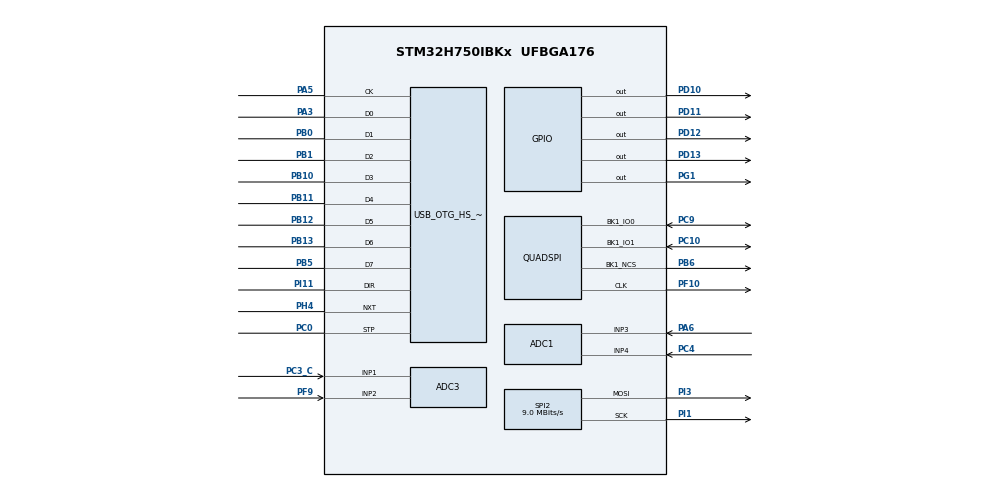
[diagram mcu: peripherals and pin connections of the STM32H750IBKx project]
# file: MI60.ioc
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ADC1.Channel-0\#ChannelRegularConversion=ADC_CHANNEL_3
ADC1.Channel-1\#ChannelRegularConversion=ADC_CHANNEL_4
ADC1.ContinuousConvMode=ENABLE
ADC1.ConversionDataManagement=ADC_CONVERSIONDATA_DMA_CIRCULAR
ADC1.NbrOfConversion=2
ADC1.NbrOfConversionFlag=1
ADC1.OffsetNumber-0\#ChannelRegularConversion=ADC_OFFSET_NONE
ADC1.OffsetNumber-1\#ChannelRegularConversion=ADC_OFFSET_NONE
ADC1.OffsetSignedSaturation-0\#ChannelRegularConversion=DISABLE
ADC1.OffsetSignedSaturation-1\#ChannelRegularConversion=DISABLE
ADC1.Overrun=ADC_OVR_DATA_OVERWRITTEN
ADC1.OversamplingMode=ENABLE
ADC1.Rank-0\#ChannelRegularConversion=1
ADC1.Rank-1\#ChannelRegularConversion=2
ADC1.Ratio=16
ADC1.RightBitShift=ADC_RIGHTBITSHIFT_2
ADC1.SamplingTime-0\#ChannelRegularConversion=ADC_SAMPLETIME_1CYCLE_5
ADC1.SamplingTime-1\#ChannelRegularConversion=ADC_SAMPLETIME_1CYCLE_5
ADC1.master=1
ADC3.Channel-2\#ChannelRegularConversion=ADC_CHANNEL_1
ADC3.Channel-3\#ChannelRegularConversion=ADC_CHANNEL_2
ADC3.ClockPrescalerADC3=ADC_CLOCK_ASYNC_DIV8
ADC3.ContinuousConvMode=ENABLE
ADC3.ConversionDataManagement=ADC_CONVERSIONDATA_DMA_CIRCULAR
ADC3.DiscontinuousConvMode=DISABLE
ADC3.NbrOfConversion=2
ADC3.NbrOfConversionFlag=1
ADC3.OffsetNumber-2\#ChannelRegularConversion=ADC_OFFSET_NONE
ADC3.OffsetNumber-3\#ChannelRegularConversion=ADC_OFFSET_NONE
ADC3.OffsetSignedSaturation-2\#ChannelRegularConversion=DISABLE
ADC3.OffsetSignedSaturation-3\#ChannelRegularConversion=DISABLE
ADC3.Overrun=ADC_OVR_DATA_OVERWRITTEN
ADC3.OversamplingMode=ENABLE
ADC3.Rank-2\#ChannelRegularConversion=1
ADC3.Rank-3\#ChannelRegularConversion=2
ADC3.Ratio=16
ADC3.RightBitShift=ADC_RIGHTBITSHIFT_2
ADC3.SamplingTime-2\#ChannelRegularConversion=ADC_SAMPLETIME_1CYCLE_5
ADC3.SamplingTime-3\#ChannelRegularConversion=ADC_SAMPLETIME_1CYCLE_5
Bdma.ADC3.0.Direction=DMA_PERIPH_TO_MEMORY
Bdma.ADC3.0.EventEnable=DISABLE
Bdma.ADC3.0.Instance=BDMA_Channel0
Bdma.ADC3.0.MemDataAlignment=DMA_MDATAALIGN_HALFWORD
Bdma.ADC3.0.MemInc=DMA_MINC_ENABLE
Bdma.ADC3.0.Mode=DMA_CIRCULAR
Bdma.ADC3.0.PeriphDataAlignment=DMA_PDATAALIGN_HALFWORD
Bdma.ADC3.0.PeriphInc=DMA_PINC_DISABLE
Bdma.ADC3.0.Polarity=HAL_DMAMUX_REQ_GEN_RISING
Bdma.ADC3.0.Priority=DMA_PRIORITY_VERY_HIGH
Bdma.ADC3.0.RequestNumber=1
Bdma.ADC3.0.SignalID=NONE
Bdma.ADC3.0.SyncEnable=DISABLE
Bdma.ADC3.0.SyncPolarity=HAL_DMAMUX_SYNC_NO_EVENT
Bdma.ADC3.0.SyncRequestNumber=1
Bdma.ADC3.0.SyncSignalID=NONE
Bdma.Request0=ADC3
Bdma.RequestsNb=1
CORTEX_M7.AccessPermission_S-Cortex_Memory_Protection_Unit_Region1_Settings_S=MPU_REGION_FULL_ACCESS
CORTEX_M7.AccessPermission_S-Cortex_Memory_Protection_Unit_Region2_Settings_S=MPU_REGION_FULL_ACCESS
CORTEX_M7.AccessPermission_S-Cortex_Memory_Protection_Unit_Region3_Settings_S=MPU_REGION_FULL_ACCESS
CORTEX_M7.AccessPermission_S-Cortex_Memory_Protection_Unit_Region4_Settings_S=MPU_REGION_FULL_ACCESS
CORTEX_M7.AccessPermission_S-Cortex_Memory_Protection_Unit_Region5_Settings_S=MPU_REGION_FULL_ACCESS
CORTEX_M7.AccessPermission_Spec=MPU_REGION_FULL_ACCESS
CORTEX_M7.BaseAddress_S-Cortex_Memory_Protection_Unit_Region1_Settings_S=0x60000000
CORTEX_M7.BaseAddress_S-Cortex_Memory_Protection_Unit_Region2_Settings_S=0x30000000
CORTEX_M7.BaseAddress_S-Cortex_Memory_Protection_Unit_Region3_Settings_S=0x30020000
CORTEX_M7.BaseAddress_S-Cortex_Memory_Protection_Unit_Region4_Settings_S=0x30040000
CORTEX_M7.BaseAddress_S-Cortex_Memory_Protection_Unit_Region5_Settings_S=0x38000000
CORTEX_M7.BaseAddress_Spec=0x24000000
CORTEX_M7.CPU_DCache=Enabled
CORTEX_M7.CPU_ICache=Enabled
CORTEX_M7.DisableExec_Spec=MPU_INSTRUCTION_ACCESS_ENABLE
CORTEX_M7.Enable_S-Cortex_Memory_Protection_Unit_Region1_Settings_S=MPU_REGION_ENABLE
CORTEX_M7.Enable_S-Cortex_Memory_Protection_Unit_Region2_Settings_S=MPU_REGION_ENABLE
CORTEX_M7.Enable_S-Cortex_Memory_Protection_Unit_Region3_Settings_S=MPU_REGION_ENABLE
CORTEX_M7.Enable_S-Cortex_Memory_Protection_Unit_Region4_Settings_S=MPU_REGION_ENABLE
CORTEX_M7.Enable_S-Cortex_Memory_Protection_Unit_Region5_Settings_S=MPU_REGION_ENABLE
CORTEX_M7.IsBufferable_S-Cortex_Memory_Protection_Unit_Region1_Settings_S=MPU_ACCESS_BUFFERABLE
CORTEX_M7.IsBufferable_Spec=MPU_ACCESS_BUFFERABLE
CORTEX_M7.IsCacheable_S-Cortex_Memory_Protection_Unit_Region2_Settings_S=MPU_ACCESS_CACHEABLE
CORTEX_M7.IsCacheable_S-Cortex_Memory_Protection_Unit_Region3_Settings_S=MPU_ACCESS_CACHEABLE
CORTEX_M7.IsCacheable_S-Cortex_Memory_Protection_Unit_Region4_Settings_S=MPU_ACCESS_CACHEABLE
CORTEX_M7.IsCacheable_S-Cortex_Memory_Protection_Unit_Region5_Settings_S=MPU_ACCESS_CACHEABLE
CORTEX_M7.IsCacheable_Spec=MPU_ACCESS_CACHEABLE
CORTEX_M7.IsShareable_Spec=MPU_ACCESS_NOT_SHAREABLE
CORTEX_M7.MPU_Control=MPU_HFNMI_PRIVDEF
CORTEX_M7.Size_S-Cortex_Memory_Protection_Unit_Region1_Settings_S=MPU_REGION_SIZE_64KB
CORTEX_M7.Size_S-Cortex_Memory_Protection_Unit_Region2_Settings_S=MPU_REGION_SIZE_128KB
CORTEX_M7.Size_S-Cortex_Memory_Protection_Unit_Region3_Settings_S=MPU_REGION_SIZE_128KB
CORTEX_M7.Size_S-Cortex_Memory_Protection_Unit_Region4_Settings_S=MPU_REGION_SIZE_32KB
CORTEX_M7.Size_S-Cortex_Memory_Protection_Unit_Region5_Settings_S=MPU_REGION_SIZE_64KB
CORTEX_M7.Size_Spec=MPU_REGION_SIZE_512KB
CORTEX_M7.SubRegionDisable_Spec=0x0
CORTEX_M7.TypeExtField_Spec=MPU_TEX_LEVEL1
CORTEX_M7.default_mode_Activation=1
Dma.ADC1.1.Direction=DMA_PERIPH_TO_MEMORY
Dma.ADC1.1.EventEnable=DISABLE
Dma.ADC1.1.FIFOMode=DMA_FIFOMODE_DISABLE
Dma.ADC1.1.Instance=DMA1_Stream5
Dma.ADC1.1.MemDataAlignment=DMA_MDATAALIGN_HALFWORD
Dma.ADC1.1.MemInc=DMA_MINC_ENABLE
Dma.ADC1.1.Mode=DMA_CIRCULAR
Dma.ADC1.1.PeriphDataAlignment=DMA_PDATAALIGN_HALFWORD
Dma.ADC1.1.PeriphInc=DMA_PINC_DISABLE
Dma.ADC1.1.Polarity=HAL_DMAMUX_REQ_GEN_RISING
Dma.ADC1.1.Priority=DMA_PRIORITY_VERY_HIGH
Dma.ADC1.1.RequestNumber=1
Dma.ADC1.1.SignalID=NONE
Dma.ADC1.1.SyncEnable=DISABLE
Dma.ADC1.1.SyncPolarity=HAL_DMAMUX_SYNC_NO_EVENT
Dma.ADC1.1.SyncRequestNumber=1
Dma.ADC1.1.SyncSignalID=NONE
Dma.Request0=SPI2_TX
Dma.Request1=ADC1
Dma.SPI2_TX.0.Direction=DMA_MEMORY_TO_PERIPH
Dma.SPI2_TX.0.EventEnable=DISABLE
Dma.SPI2_TX.0.FIFOMode=DMA_FIFOMODE_DISABLE
Dma.SPI2_TX.0.Instance=DMA1_Stream0
Dma.SPI2_TX.0.MemDataAlignment=DMA_MDATAALIGN_BYTE
Dma.SPI2_TX.0.MemInc=DMA_MINC_ENABLE
Dma.SPI2_TX.0.Mode=DMA_NORMAL
Dma.SPI2_TX.0.PeriphDataAlignment=DMA_PDATAALIGN_BYTE
Dma.SPI2_TX.0.PeriphInc=DMA_PINC_DISABLE
Dma.SPI2_TX.0.Polarity=HAL_DMAMUX_REQ_GEN_RISING
Dma.SPI2_TX.0.Priority=DMA_PRIORITY_LOW
Dma.SPI2_TX.0.RequestNumber=1
Dma.SPI2_TX.0.SignalID=NONE
Dma.SPI2_TX.0.SyncEnable=DISABLE
Dma.SPI2_TX.0.SyncPolarity=HAL_DMAMUX_SYNC_NO_EVENT
Dma.SPI2_TX.0.SyncRequestNumber=1
Dma.SPI2_TX.0.SyncSignalID=NONE
Mcu.Family=STM32H7
Mcu.Name=STM32H750IBKx
Mcu.Package=UFBGA176
NVIC.ADC3_IRQn=true\:0\:0\:false\:false\:true\:true\:true\:true
NVIC.ADC_IRQn=true\:0\:0\:false\:false\:true\:true\:true\:true
NVIC.BDMA_Channel0_IRQn=true\:0\:0\:false\:false\:true\:false\:true\:true
NVIC.DMA1_Stream0_IRQn=true\:2\:0\:true\:false\:true\:false\:true\:true
NVIC.DMA1_Stream5_IRQn=true\:0\:0\:true\:false\:true\:false\:true\:true
NVIC.OTG_HS_IRQn=true\:0\:0\:false\:false\:true\:true\:true\:true
NVIC.PriorityGroup=NVIC_PRIORITYGROUP_4
NVIC.SPI2_IRQn=true\:2\:0\:true\:false\:true\:false\:true\:true
NVIC.TIM5_IRQn=true\:0\:0\:false\:false\:true\:true\:true\:true
PA13\ (JTMS/SWDIO).Mode=Serial_Wire
PA13\ (JTMS/SWDIO).Signal=DEBUG_JTMS-SWDIO
PA14\ (JTCK/SWCLK).Mode=Serial_Wire
PA14\ (JTCK/SWCLK).Signal=DEBUG_JTCK-SWCLK
PA3.Mode=Device_HS
PA3.Signal=USB_OTG_HS_ULPI_D0
PA5.Mode=Device_HS
PA5.Signal=USB_OTG_HS_ULPI_CK
PA6.Signal=ADCx_INP3
PB0.Mode=Device_HS
PB0.Signal=USB_OTG_HS_ULPI_D1
PB1.Mode=Device_HS
PB1.Signal=USB_OTG_HS_ULPI_D2
PB10.Mode=Device_HS
PB10.Signal=USB_OTG_HS_ULPI_D3
PB11.Mode=Device_HS
PB11.Signal=USB_OTG_HS_ULPI_D4
PB12.Mode=Device_HS
PB12.Signal=USB_OTG_HS_ULPI_D5
PB13.Mode=Device_HS
PB13.Signal=USB_OTG_HS_ULPI_D6
PB5.Mode=Device_HS
PB5.Signal=USB_OTG_HS_ULPI_D7
PB6.Mode=Single Bank 1 2IOs
PB6.Signal=QUADSPI_BK1_NCS
PC0.Mode=Device_HS
PC0.Signal=USB_OTG_HS_ULPI_STP
PC10.Mode=Single Bank 1 2IOs
PC10.Signal=QUADSPI_BK1_IO1
PC3_C.Mode=IN1-Single-Ended
PC3_C.Signal=ADC3_INP1
PC4.Signal=ADCx_INP4
PC9.Mode=Single Bank 1 2IOs
PC9.Signal=QUADSPI_BK1_IO0
PD10.GPIO_ModeDefaultOutputPP=GPIO_MODE_OUTPUT_OD
PD10.GPIO_PuPd=GPIO_PULLUP
PD10.GPIO_Speed=GPIO_SPEED_FREQ_VERY_HIGH
PD10.Signal=GPIO_Output
PD11.GPIO_ModeDefaultOutputPP=GPIO_MODE_OUTPUT_OD
PD11.GPIO_PuPd=GPIO_PULLUP
PD11.GPIO_Speed=GPIO_SPEED_FREQ_VERY_HIGH
PD11.Signal=GPIO_Output
PD12.GPIO_ModeDefaultOutputPP=GPIO_MODE_OUTPUT_OD
PD12.GPIO_PuPd=GPIO_PULLUP
PD12.GPIO_Speed=GPIO_SPEED_FREQ_VERY_HIGH
PD12.Signal=GPIO_Output
PD13.GPIO_ModeDefaultOutputPP=GPIO_MODE_OUTPUT_OD
PD13.GPIO_PuPd=GPIO_PULLUP
PD13.GPIO_Speed=GPIO_SPEED_FREQ_VERY_HIGH
PD13.Signal=GPIO_Output
PF10.Mode=Single Bank 1 2IOs
PF10.Signal=QUADSPI_CLK
PF9.Mode=IN2-Single-Ended
PF9.Signal=ADC3_INP2
PG1.Signal=GPIO_Output
PH0-OSC_IN\ (PH0).Mode=HSE-External-Oscillator
PH0-OSC_IN\ (PH0).Signal=RCC_OSC_IN
PH1-OSC_OUT\ (PH1).Mode=HSE-External-Oscillator
PH1-OSC_OUT\ (PH1).Signal=RCC_OSC_OUT
PH4.Mode=Device_HS
PH4.Signal=USB_OTG_HS_ULPI_NXT
PI1.Mode=TX_Only_Simplex_Unidirect_Master
PI1.Signal=SPI2_SCK
PI11.Mode=Device_HS
PI11.Signal=USB_OTG_HS_ULPI_DIR
PI3.Mode=TX_Only_Simplex_Unidirect_Master
PI3.Signal=SPI2_MOSI
ProjectManager.HeapSize=0x800
ProjectManager.StackSize=0x1000
ProjectManager.TargetToolchain=STM32CubeIDE
RCC.ADCFreq_Value=72000000
RCC.APB1Freq_Value=120000000
RCC.APB2Freq_Value=120000000
RCC.APB3Freq_Value=120000000
RCC.APB4Freq_Value=120000000
RCC.CortexFreq_Value=480000000
RCC.D1PPRE=RCC_APB3_DIV2
RCC.D2PPRE1=RCC_APB1_DIV2
RCC.D2PPRE2=RCC_APB2_DIV2
RCC.D3PPRE=RCC_APB4_DIV2
RCC.DIVM1=4
RCC.DIVM2=4
RCC.DIVM3=12
RCC.DIVN1=80
RCC.DIVN2=18
RCC.DIVN3=80
RCC.DIVP2=3
RCC.DIVP3=4
RCC.DIVR3=20
RCC.HCLKFreq_Value=240000000
RCC.HPRE=RCC_HCLK_DIV2
RCC.HSE_VALUE=48000000
RCC.PLL2FRACN=0
RCC.PLL3FRACN=0
RCC.PLLFRACN=0
RCC.PLLSourceVirtual=RCC_PLLSOURCE_HSE
RCC.ProductRev=revV
RCC.SPI123CLockSelection=RCC_SPI123CLKSOURCE_PLL2
RCC.SYSCLKFreq_VALUE=480000000
RCC.SYSCLKSource=RCC_SYSCLKSOURCE_PLLCLK
RCC.USBCLockSelection=RCC_USBCLKSOURCE_HSI48
RCC.USBFreq_Value=48000000
SH.ADCx_INP3.0=ADC1_INP3,IN3-Single-Ended
SH.ADCx_INP4.0=ADC1_INP4,IN4-Single-Ended
SPI2.BaudRatePrescaler=SPI_BAUDRATEPRESCALER_8
SPI2.CLKPhase=SPI_PHASE_1EDGE
SPI2.CalculateBaudRate=9.0 MBits/s
SPI2.DataSize=SPI_DATASIZE_8BIT
SPI2.Direction=SPI_DIRECTION_2LINES_TXONLY
SPI2.Mode=SPI_MODE_MASTER
SPI2.VirtualType=VM_MASTER
TIM5.Period=124
TIM5.Prescaler=479
USB_DEVICE.CLASS_NAME_HS=CUSTOM_HID
USB_DEVICE.CUSTOM_HID_HS_BINTERVAL=0x1
USB_DEVICE.USBD_CUSTOMHID_OUTREPORT_BUF_SIZE-CUSTOM_HID_HS=64
USB_DEVICE.USBD_CUSTOM_HID_REPORT_DESC_SIZE-CUSTOM_HID_HS=89
USB_DEVICE.VirtualMode-CUSTOM_HID_HS=CustomHid
USB_DEVICE.VirtualModeHS=Custom_Hid_HS
USB_OTG_HS.VirtualMode-Device_HS=Device_HS
USB_OTG_HS.dma_enable-Device_HS=ENABLE
VP_RNG_VS_RNG.Mode=RNG_Activate
VP_TIM5_VS_ClockSourceINT.Mode=Internal
VP_USB_DEVICE_VS_USB_DEVICE_CUSTOM_HID_HS.Mode=CUSTOM_HID_HS
board=custom

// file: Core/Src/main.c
/* USER CODE BEGIN Header */
/**
  ******************************************************************************
  * @file           : main.c
  * @brief          : Main program body
  ******************************************************************************
  * @attention
  *
  * Copyright (c) 2023 STMicroelectronics.
  * All rights reserved.
  *
  * This software is licensed under terms that can be found in the LICENSE file
  * in the root directory of this software component.
  * If no LICENSE file comes with this software, it is provided AS-IS.
  *
  ******************************************************************************
  */
/* USER CODE END Header */
#include "main.h"
#include "usb_device.h"

/* USER CODE BEGIN Includes */
#include "common_inc.h"
/* USER CODE END Includes */

ADC_HandleTypeDef hadc1;
ADC_HandleTypeDef hadc3;
DMA_HandleTypeDef hdma_adc1;
DMA_HandleTypeDef hdma_adc3;

QSPI_HandleTypeDef hqspi;

RNG_HandleTypeDef hrng;

SPI_HandleTypeDef hspi2;
DMA_HandleTypeDef hdma_spi2_tx;

TIM_HandleTypeDef htim5;

/* USER CODE BEGIN PV */
ALIGN_32BYTES(__attribute__((section(".RAM_D3"))) uint16_t ADC_BUF[4]);    //tip
__attribute__((section(".RAM_D1"))) uint8_t sfBuffer[4096];  //SPI flash buffer
__attribute__((section(".RAM_D1"))) uint8_t txBuffer[4096];  //todo
/* USER CODE END PV */

void SystemClock_Config(void);
void PeriphCommonClock_Config(void);
static void MPU_Config(void);
static void MX_GPIO_Init(void);
static void MX_BDMA_Init(void);
static void MX_DMA_Init(void);
static void MX_ADC3_Init(void);
static void MX_SPI2_Init(void);
static void MX_TIM5_Init(void);
static void MX_ADC1_Init(void);
static void MX_RNG_Init(void);
static void MX_QUADSPI_Init(void);

int main(void)
{

  /* MPU Configuration--------------------------------------------------------*/
  MPU_Config();

  /* Enable I-Cache---------------------------------------------------------*/
  SCB_EnableICache();

  /* Enable D-Cache---------------------------------------------------------*/
  SCB_EnableDCache();

  /* MCU Configuration--------------------------------------------------------*/

  /* Reset of all peripherals, Initializes the Flash interface and the Systick. */
  HAL_Init();

  /* Configure the system clock */
  SystemClock_Config();

/* Configure the peripherals common clocks */
  PeriphCommonClock_Config();

  /* Initialize all configured peripherals */
  MX_GPIO_Init();
  MX_BDMA_Init();
  MX_DMA_Init();
  MX_USB_DEVICE_Init();
  MX_ADC3_Init();
  MX_SPI2_Init();
  MX_TIM5_Init();
  MX_ADC1_Init();
  MX_RNG_Init();
  MX_QUADSPI_Init();
  /* USER CODE BEGIN 2 */
  //ADC self calibration
    HAL_ADCEx_Calibration_Start(&hadc3, ADC_CALIB_OFFSET_LINEARITY, ADC_SINGLE_ENDED);
    HAL_ADCEx_Calibration_Start(&hadc1, ADC_CALIB_OFFSET_LINEARITY, ADC_SINGLE_ENDED);
    //main function
    KeyboardMain();
  /* USER CODE END 2 */

  /* Infinite loop */
  while (1)
  {

  }
}

void SystemClock_Config(void)
{
  RCC_OscInitTypeDef RCC_OscInitStruct = {0};
  RCC_ClkInitTypeDef RCC_ClkInitStruct = {0};

  /** Supply configuration update enable
  */
  HAL_PWREx_ConfigSupply(PWR_LDO_SUPPLY);

  /** Configure the main internal regulator output voltage
  */
  __HAL_PWR_VOLTAGESCALING_CONFIG(PWR_REGULATOR_VOLTAGE_SCALE1);

  while(!__HAL_PWR_GET_FLAG(PWR_FLAG_VOSRDY)) {}

  __HAL_RCC_SYSCFG_CLK_ENABLE();
  __HAL_PWR_VOLTAGESCALING_CONFIG(PWR_REGULATOR_VOLTAGE_SCALE0);

  while(!__HAL_PWR_GET_FLAG(PWR_FLAG_VOSRDY)) {}

  /** Initializes the RCC Oscillators according to the specified parameters
  * in the RCC_OscInitTypeDef structure.
  */
  RCC_OscInitStruct.OscillatorType = RCC_OSCILLATORTYPE_HSI48|RCC_OSCILLATORTYPE_HSE;
  RCC_OscInitStruct.HSEState = RCC_HSE_ON;
  RCC_OscInitStruct.HSI48State = RCC_HSI48_ON;
  RCC_OscInitStruct.PLL.PLLState = RCC_PLL_ON;
  RCC_OscInitStruct.PLL.PLLSource = RCC_PLLSOURCE_HSE;
  RCC_OscInitStruct.PLL.PLLM = 4;
  RCC_OscInitStruct.PLL.PLLN = 80;
  RCC_OscInitStruct.PLL.PLLP = 2;
  RCC_OscInitStruct.PLL.PLLQ = 2;
  RCC_OscInitStruct.PLL.PLLR = 2;
  RCC_OscInitStruct.PLL.PLLRGE = RCC_PLL1VCIRANGE_3;
  RCC_OscInitStruct.PLL.PLLVCOSEL = RCC_PLL1VCOWIDE;
  RCC_OscInitStruct.PLL.PLLFRACN = 0;
  if (HAL_RCC_OscConfig(&RCC_OscInitStruct) != HAL_OK)
  {
    Error_Handler();
  }

  /** Initializes the CPU, AHB and APB buses clocks
  */
  RCC_ClkInitStruct.ClockType = RCC_CLOCKTYPE_HCLK|RCC_CLOCKTYPE_SYSCLK
                              |RCC_CLOCKTYPE_PCLK1|RCC_CLOCKTYPE_PCLK2
                              |RCC_CLOCKTYPE_D3PCLK1|RCC_CLOCKTYPE_D1PCLK1;
  RCC_ClkInitStruct.SYSCLKSource = RCC_SYSCLKSOURCE_PLLCLK;
  RCC_ClkInitStruct.SYSCLKDivider = RCC_SYSCLK_DIV1;
  RCC_ClkInitStruct.AHBCLKDivider = RCC_HCLK_DIV2;
  RCC_ClkInitStruct.APB3CLKDivider = RCC_APB3_DIV2;
  RCC_ClkInitStruct.APB1CLKDivider = RCC_APB1_DIV2;
  RCC_ClkInitStruct.APB2CLKDivider = RCC_APB2_DIV2;
  RCC_ClkInitStruct.APB4CLKDivider = RCC_APB4_DIV2;

  if (HAL_RCC_ClockConfig(&RCC_ClkInitStruct, FLASH_LATENCY_4) != HAL_OK)
  {
    Error_Handler();
  }
}

void PeriphCommonClock_Config(void)
{
  RCC_PeriphCLKInitTypeDef PeriphClkInitStruct = {0};

  /** Initializes the peripherals clock
  */
  PeriphClkInitStruct.PeriphClockSelection = RCC_PERIPHCLK_ADC|RCC_PERIPHCLK_SPI2;
  PeriphClkInitStruct.PLL2.PLL2M = 4;
  PeriphClkInitStruct.PLL2.PLL2N = 18;
  PeriphClkInitStruct.PLL2.PLL2P = 3;
  PeriphClkInitStruct.PLL2.PLL2Q = 2;
  PeriphClkInitStruct.PLL2.PLL2R = 2;
  PeriphClkInitStruct.PLL2.PLL2RGE = RCC_PLL2VCIRANGE_3;
  PeriphClkInitStruct.PLL2.PLL2VCOSEL = RCC_PLL2VCOWIDE;
  PeriphClkInitStruct.PLL2.PLL2FRACN = 0;
  PeriphClkInitStruct.Spi123ClockSelection = RCC_SPI123CLKSOURCE_PLL2;
  PeriphClkInitStruct.AdcClockSelection = RCC_ADCCLKSOURCE_PLL2;
  if (HAL_RCCEx_PeriphCLKConfig(&PeriphClkInitStruct) != HAL_OK)
  {
    Error_Handler();
  }
}

static void MX_ADC1_Init(void)
{

  ADC_MultiModeTypeDef multimode = {0};
  ADC_ChannelConfTypeDef sConfig = {0};

  /** Common config
  */
  hadc1.Instance = ADC1;
  hadc1.Init.ClockPrescaler = ADC_CLOCK_ASYNC_DIV1;
  hadc1.Init.Resolution = ADC_RESOLUTION_16B;
  hadc1.Init.ScanConvMode = ADC_SCAN_ENABLE;
  hadc1.Init.EOCSelection = ADC_EOC_SINGLE_CONV;
  hadc1.Init.LowPowerAutoWait = DISABLE;
  hadc1.Init.ContinuousConvMode = ENABLE;
  hadc1.Init.NbrOfConversion = 2;
  hadc1.Init.DiscontinuousConvMode = DISABLE;
  hadc1.Init.ExternalTrigConv = ADC_SOFTWARE_START;
  hadc1.Init.ExternalTrigConvEdge = ADC_EXTERNALTRIGCONVEDGE_NONE;
  hadc1.Init.ConversionDataManagement = ADC_CONVERSIONDATA_DMA_CIRCULAR;
  hadc1.Init.Overrun = ADC_OVR_DATA_OVERWRITTEN;
  hadc1.Init.LeftBitShift = ADC_LEFTBITSHIFT_NONE;
  hadc1.Init.OversamplingMode = ENABLE;
  hadc1.Init.Oversampling.Ratio = 16;
  hadc1.Init.Oversampling.RightBitShift = ADC_RIGHTBITSHIFT_2;
  hadc1.Init.Oversampling.TriggeredMode = ADC_TRIGGEREDMODE_SINGLE_TRIGGER;
  hadc1.Init.Oversampling.OversamplingStopReset = ADC_REGOVERSAMPLING_CONTINUED_MODE;
  if (HAL_ADC_Init(&hadc1) != HAL_OK)
  {
    Error_Handler();
  }

  /** Configure the ADC multi-mode
  */
  multimode.Mode = ADC_MODE_INDEPENDENT;
  if (HAL_ADCEx_MultiModeConfigChannel(&hadc1, &multimode) != HAL_OK)
  {
    Error_Handler();
  }

  /** Configure Regular Channel
  */
  sConfig.Channel = ADC_CHANNEL_3;
  sConfig.Rank = ADC_REGULAR_RANK_1;
  sConfig.SamplingTime = ADC_SAMPLETIME_1CYCLE_5;
  sConfig.SingleDiff = ADC_SINGLE_ENDED;
  sConfig.OffsetNumber = ADC_OFFSET_NONE;
  sConfig.Offset = 0;
  sConfig.OffsetSignedSaturation = DISABLE;
  if (HAL_ADC_ConfigChannel(&hadc1, &sConfig) != HAL_OK)
  {
    Error_Handler();
  }

  /** Configure Regular Channel
  */
  sConfig.Channel = ADC_CHANNEL_4;
  sConfig.Rank = ADC_REGULAR_RANK_2;
  if (HAL_ADC_ConfigChannel(&hadc1, &sConfig) != HAL_OK)
  {
    Error_Handler();
  }

}

static void MX_ADC3_Init(void)
{

  ADC_ChannelConfTypeDef sConfig = {0};

  /** Common config
  */
  hadc3.Instance = ADC3;
  hadc3.Init.Resolution = ADC_RESOLUTION_16B;
  hadc3.Init.ScanConvMode = ADC_SCAN_ENABLE;
  hadc3.Init.EOCSelection = ADC_EOC_SINGLE_CONV;
  hadc3.Init.LowPowerAutoWait = DISABLE;
  hadc3.Init.ContinuousConvMode = ENABLE;
  hadc3.Init.NbrOfConversion = 2;
  hadc3.Init.DiscontinuousConvMode = DISABLE;
  hadc3.Init.ExternalTrigConv = ADC_SOFTWARE_START;
  hadc3.Init.ExternalTrigConvEdge = ADC_EXTERNALTRIGCONVEDGE_NONE;
  hadc3.Init.ConversionDataManagement = ADC_CONVERSIONDATA_DMA_CIRCULAR;
  hadc3.Init.Overrun = ADC_OVR_DATA_OVERWRITTEN;
  hadc3.Init.LeftBitShift = ADC_LEFTBITSHIFT_NONE;
  hadc3.Init.OversamplingMode = ENABLE;
  hadc3.Init.Oversampling.Ratio = 16;
  hadc3.Init.Oversampling.RightBitShift = ADC_RIGHTBITSHIFT_2;
  hadc3.Init.Oversampling.TriggeredMode = ADC_TRIGGEREDMODE_SINGLE_TRIGGER;
  hadc3.Init.Oversampling.OversamplingStopReset = ADC_REGOVERSAMPLING_CONTINUED_MODE;
  if (HAL_ADC_Init(&hadc3) != HAL_OK)
  {
    Error_Handler();
  }

  /** Configure Regular Channel
  */
  sConfig.Channel = ADC_CHANNEL_1;
  sConfig.Rank = ADC_REGULAR_RANK_1;
  sConfig.SamplingTime = ADC_SAMPLETIME_1CYCLE_5;
  sConfig.SingleDiff = ADC_SINGLE_ENDED;
  sConfig.OffsetNumber = ADC_OFFSET_NONE;
  sConfig.Offset = 0;
  sConfig.OffsetSignedSaturation = DISABLE;
  if (HAL_ADC_ConfigChannel(&hadc3, &sConfig) != HAL_OK)
  {
    Error_Handler();
  }

  /** Configure Regular Channel
  */
  sConfig.Channel = ADC_CHANNEL_2;
  sConfig.Rank = ADC_REGULAR_RANK_2;
  if (HAL_ADC_ConfigChannel(&hadc3, &sConfig) != HAL_OK)
  {
    Error_Handler();
  }

}

static void MX_QUADSPI_Init(void)
{

  /* QUADSPI parameter configuration*/
  hqspi.Instance = QUADSPI;
  hqspi.Init.ClockPrescaler = 255;
  hqspi.Init.FifoThreshold = 1;
  hqspi.Init.SampleShifting = QSPI_SAMPLE_SHIFTING_NONE;
  hqspi.Init.FlashSize = 1;
  hqspi.Init.ChipSelectHighTime = QSPI_CS_HIGH_TIME_1_CYCLE;
  hqspi.Init.ClockMode = QSPI_CLOCK_MODE_0;
  hqspi.Init.FlashID = QSPI_FLASH_ID_1;
  hqspi.Init.DualFlash = QSPI_DUALFLASH_DISABLE;
  if (HAL_QSPI_Init(&hqspi) != HAL_OK)
  {
    Error_Handler();
  }

}

static void MX_RNG_Init(void)
{

  hrng.Instance = RNG;
  hrng.Init.ClockErrorDetection = RNG_CED_ENABLE;
  if (HAL_RNG_Init(&hrng) != HAL_OK)
  {
    Error_Handler();
  }

}

static void MX_SPI2_Init(void)
{

  /* SPI2 parameter configuration*/
  hspi2.Instance = SPI2;
  hspi2.Init.Mode = SPI_MODE_MASTER;
  hspi2.Init.Direction = SPI_DIRECTION_2LINES_TXONLY;
  hspi2.Init.DataSize = SPI_DATASIZE_8BIT;
  hspi2.Init.CLKPolarity = SPI_POLARITY_LOW;
  hspi2.Init.CLKPhase = SPI_PHASE_1EDGE;
  hspi2.Init.NSS = SPI_NSS_SOFT;
  hspi2.Init.BaudRatePrescaler = SPI_BAUDRATEPRESCALER_8;
  hspi2.Init.FirstBit = SPI_FIRSTBIT_MSB;
  hspi2.Init.TIMode = SPI_TIMODE_DISABLE;
  hspi2.Init.CRCCalculation = SPI_CRCCALCULATION_DISABLE;
  hspi2.Init.CRCPolynomial = 0x0;
  hspi2.Init.NSSPMode = SPI_NSS_PULSE_ENABLE;
  hspi2.Init.NSSPolarity = SPI_NSS_POLARITY_LOW;
  hspi2.Init.FifoThreshold = SPI_FIFO_THRESHOLD_01DATA;
  hspi2.Init.TxCRCInitializationPattern = SPI_CRC_INITIALIZATION_ALL_ZERO_PATTERN;
  hspi2.Init.RxCRCInitializationPattern = SPI_CRC_INITIALIZATION_ALL_ZERO_PATTERN;
  hspi2.Init.MasterSSIdleness = SPI_MASTER_SS_IDLENESS_00CYCLE;
  hspi2.Init.MasterInterDataIdleness = SPI_MASTER_INTERDATA_IDLENESS_00CYCLE;
  hspi2.Init.MasterReceiverAutoSusp = SPI_MASTER_RX_AUTOSUSP_DISABLE;
  hspi2.Init.MasterKeepIOState = SPI_MASTER_KEEP_IO_STATE_DISABLE;
  hspi2.Init.IOSwap = SPI_IO_SWAP_DISABLE;
  if (HAL_SPI_Init(&hspi2) != HAL_OK)
  {
    Error_Handler();
  }

}

static void MX_TIM5_Init(void)
{

  TIM_ClockConfigTypeDef sClockSourceConfig = {0};
  TIM_MasterConfigTypeDef sMasterConfig = {0};

  htim5.Instance = TIM5;
  htim5.Init.Prescaler = 479;
  htim5.Init.CounterMode = TIM_COUNTERMODE_UP;
  htim5.Init.Period = 124;
  htim5.Init.ClockDivision = TIM_CLOCKDIVISION_DIV1;
  htim5.Init.AutoReloadPreload = TIM_AUTORELOAD_PRELOAD_DISABLE;
  if (HAL_TIM_Base_Init(&htim5) != HAL_OK)
  {
    Error_Handler();
  }
  sClockSourceConfig.ClockSource = TIM_CLOCKSOURCE_INTERNAL;
  if (HAL_TIM_ConfigClockSource(&htim5, &sClockSourceConfig) != HAL_OK)
  {
    Error_Handler();
  }
  sMasterConfig.MasterOutputTrigger = TIM_TRGO_RESET;
  sMasterConfig.MasterSlaveMode = TIM_MASTERSLAVEMODE_DISABLE;
  if (HAL_TIMEx_MasterConfigSynchronization(&htim5, &sMasterConfig) != HAL_OK)
  {
    Error_Handler();
  }

}

static void MX_BDMA_Init(void)
{

  /* DMA controller clock enable */
  __HAL_RCC_BDMA_CLK_ENABLE();

  /* DMA interrupt init */
  /* BDMA_Channel0_IRQn interrupt configuration */
  HAL_NVIC_SetPriority(BDMA_Channel0_IRQn, 0, 0);
  HAL_NVIC_EnableIRQ(BDMA_Channel0_IRQn);

}

static void MX_DMA_Init(void)
{

  /* DMA controller clock enable */
  __HAL_RCC_DMA1_CLK_ENABLE();

  /* DMA interrupt init */
  /* DMA1_Stream0_IRQn interrupt configuration */
  HAL_NVIC_SetPriority(DMA1_Stream0_IRQn, 2, 0);
  HAL_NVIC_EnableIRQ(DMA1_Stream0_IRQn);
  /* DMA1_Stream5_IRQn interrupt configuration */
  HAL_NVIC_SetPriority(DMA1_Stream5_IRQn, 0, 0);
  HAL_NVIC_EnableIRQ(DMA1_Stream5_IRQn);

}

static void MX_GPIO_Init(void)
{
  GPIO_InitTypeDef GPIO_InitStruct = {0};

  /* GPIO Ports Clock Enable */
  __HAL_RCC_GPIOB_CLK_ENABLE();
  __HAL_RCC_GPIOA_CLK_ENABLE();
  __HAL_RCC_GPIOC_CLK_ENABLE();
  __HAL_RCC_GPIOI_CLK_ENABLE();
  __HAL_RCC_GPIOH_CLK_ENABLE();
  __HAL_RCC_GPIOF_CLK_ENABLE();
  __HAL_RCC_GPIOG_CLK_ENABLE();
  __HAL_RCC_GPIOD_CLK_ENABLE();

  /*Configure GPIO pin Output Level */
  HAL_GPIO_WritePin(GPIOG, GPIO_PIN_1, GPIO_PIN_RESET);

  /*Configure GPIO pin Output Level */
  HAL_GPIO_WritePin(GPIOD, GPIO_PIN_13|GPIO_PIN_12|GPIO_PIN_11|GPIO_PIN_10, GPIO_PIN_RESET);

  /*Configure GPIO pin : PG1 */
  GPIO_InitStruct.Pin = GPIO_PIN_1;
  GPIO_InitStruct.Mode = GPIO_MODE_OUTPUT_PP;
  GPIO_InitStruct.Pull = GPIO_NOPULL;
  GPIO_InitStruct.Speed = GPIO_SPEED_FREQ_LOW;
  HAL_GPIO_Init(GPIOG, &GPIO_InitStruct);

  /*Configure GPIO pins : PD13 PD12 PD11 PD10 */
  GPIO_InitStruct.Pin = GPIO_PIN_13|GPIO_PIN_12|GPIO_PIN_11|GPIO_PIN_10;
  GPIO_InitStruct.Mode = GPIO_MODE_OUTPUT_OD;
  GPIO_InitStruct.Pull = GPIO_PULLUP;
  GPIO_InitStruct.Speed = GPIO_SPEED_FREQ_VERY_HIGH;
  HAL_GPIO_Init(GPIOD, &GPIO_InitStruct);

}

/* MPU Configuration */

void MPU_Config(void)
{
  MPU_Region_InitTypeDef MPU_InitStruct = {0};

  /* Disables the MPU */
  HAL_MPU_Disable();

  /** Initializes and configures the Region and the memory to be protected
  */
  MPU_InitStruct.Enable = MPU_REGION_ENABLE;
  MPU_InitStruct.Number = MPU_REGION_NUMBER0;
  MPU_InitStruct.BaseAddress = 0x24000000;
  MPU_InitStruct.Size = MPU_REGION_SIZE_512KB;
  MPU_InitStruct.SubRegionDisable = 0x0;
  MPU_InitStruct.TypeExtField = MPU_TEX_LEVEL1;
  MPU_InitStruct.AccessPermission = MPU_REGION_FULL_ACCESS;
  MPU_InitStruct.DisableExec = MPU_INSTRUCTION_ACCESS_ENABLE;
  MPU_InitStruct.IsShareable = MPU_ACCESS_NOT_SHAREABLE;
  MPU_InitStruct.IsCacheable = MPU_ACCESS_CACHEABLE;
  MPU_InitStruct.IsBufferable = MPU_ACCESS_BUFFERABLE;

  HAL_MPU_ConfigRegion(&MPU_InitStruct);

  /** Initializes and configures the Region and the memory to be protected
  */
  MPU_InitStruct.Number = MPU_REGION_NUMBER1;
  MPU_InitStruct.BaseAddress = 0x60000000;
  MPU_InitStruct.Size = MPU_REGION_SIZE_64KB;
  MPU_InitStruct.TypeExtField = MPU_TEX_LEVEL0;
  MPU_InitStruct.IsCacheable = MPU_ACCESS_NOT_CACHEABLE;

  HAL_MPU_ConfigRegion(&MPU_InitStruct);

  /** Initializes and configures the Region and the memory to be protected
  */
  MPU_InitStruct.Number = MPU_REGION_NUMBER2;
  MPU_InitStruct.BaseAddress = 0x30000000;
  MPU_InitStruct.Size = MPU_REGION_SIZE_128KB;
  MPU_InitStruct.IsCacheable = MPU_ACCESS_CACHEABLE;
  MPU_InitStruct.IsBufferable = MPU_ACCESS_NOT_BUFFERABLE;

  HAL_MPU_ConfigRegion(&MPU_InitStruct);

  /** Initializes and configures the Region and the memory to be protected
  */
  MPU_InitStruct.Number = MPU_REGION_NUMBER3;
  MPU_InitStruct.BaseAddress = 0x30020000;

  HAL_MPU_ConfigRegion(&MPU_InitStruct);

  /** Initializes and configures the Region and the memory to be protected
  */
  MPU_InitStruct.Number = MPU_REGION_NUMBER4;
  MPU_InitStruct.BaseAddress = 0x30040000;
  MPU_InitStruct.Size = MPU_REGION_SIZE_32KB;

  HAL_MPU_ConfigRegion(&MPU_InitStruct);

  /** Initializes and configures the Region and the memory to be protected
  */
  MPU_InitStruct.Number = MPU_REGION_NUMBER5;
  MPU_InitStruct.BaseAddress = 0x38000000;
  MPU_InitStruct.Size = MPU_REGION_SIZE_64KB;

  HAL_MPU_ConfigRegion(&MPU_InitStruct);
  /* Enables the MPU */
  HAL_MPU_Enable(MPU_HFNMI_PRIVDEF);

}

void Error_Handler(void)
{
  __disable_irq();
  while (1)
  {
  }
}
